AUTOSAR XML (schema 4-0-3)
package /AUTOSAR_Dcm/ImplementationDataTypes
  61 x impl type:
    DataArrayType_DcmDspData_PlatformSoftwareVersion: category=ARRAY
      element DataArrayType: array-size=14, array-size-semantics=FIXED-SIZE, implementation-data-type=uint8
    DataArrayType_DcmDspData_InputOutputControlbyIdentifier_Supportedcheck: category=ARRAY
      element DataArrayType: array-size=4, array-size-semantics=FIXED-SIZE, implementation-data-type=uint8
    DataArrayType_DcmDspData_InputOutputRecordLocalIdentifier1: category=ARRAY
      element DataArrayType: array-size=20, array-size-semantics=FIXED-SIZE, implementation-data-type=uint8
    Dcm_ProtocolType:
      category=VALUE
      base-type=uint8
      compu {0x00=DCM_OBD_ON_CAN, 0x01=DCM_OBD_ON_FLEXRAY, 0x02=DCM_OBD_ON_IP, 0x03=DCM_UDS_ON_CAN, 0x04=DCM_UDS_ON_FLEXRAY, 0x05=DCM_UDS_ON_IP, 0x06=DCM_ROE_ON_CAN, 0x07=DCM_ROE_ON_FLEXRAY, 0x08=DCM_ROE_ON_IP, 0x09=DCM_PERIODICTRANS_ON_CAN, 0x0A=DCM_PERIODICTRANS_ON_FLEXRAY, 0x0B=DCM_PERIODICTRANS_ON_IP, 0x0C=DCM_NO_ACTIVE_PROTOCOL, 0xF0=DCM_SUPPLIER_1, 0xF1=DCM_SUPPLIER_2, 0xF2=DCM_SUPPLIER_3, 0xF3=DCM_SUPPLIER_4, 0xF4=DCM_SUPPLIER_5, 0xF5=DCM_SUPPLIER_6, 0xF6=DCM_SUPPLIER_7, 0xF7=DCM_SUPPLIER_8, 0xF8=DCM_SUPPLIER_9, 0xF9=DCM_SUPPLIER_10, 0xFA=DCM_SUPPLIER_11, 0xFB=DCM_SUPPLIER_12, 0xFC=DCM_SUPPLIER_13, 0xFD=DCM_SUPPLIER_14, 0xFE=DCM_SUPPLIER_15, 0x0E=DCM_OBD_ON_UDS, 0x0F=DCM_ZEV_ON_UDS}
      range raw 0x00..0xFE
    Dcm_ResponseDataArrayType: category=ARRAY
      element RequestDataArray: array-size=512, array-size-semantics=FIXED-SIZE, implementation-data-type=uint8
    DataArrayType_DcmDspData_SecureBootEnable: category=ARRAY
      element DataArrayType: array-size=1, array-size-semantics=FIXED-SIZE, implementation-data-type=uint8
    KeyArrayType_L10: category=ARRAY
      element KeyArrayType: array-size=256, array-size-semantics=FIXED-SIZE, implementation-data-type=uint8
    DataArrayType_DcmDspData_InputOutputControlbyIdentifier_13: category=ARRAY
      element DataArrayType: array-size=1, array-size-semantics=FIXED-SIZE, implementation-data-type=uint8
    DataArrayType_DcmDspData_ECUSoftwareUNITnumberDataIdentifier: category=ARRAY
      element DataArrayType: array-size=1, array-size-semantics=FIXED-SIZE, implementation-data-type=uint8
    Dcm_MsgLenType: category=VALUE, base-type=uint32, range raw 0..4294967295
    Dcm_PresentDateType: category=VALUE, base-type=uint8, range raw 0..255
    DataArrayType_DcmDspData_InputOutputControlbyIdentifier_18: category=ARRAY
      element DataArrayType: array-size=10, array-size-semantics=FIXED-SIZE, implementation-data-type=uint8
    DataArrayType_DcmDspData_SystemSupplierECUHardwareVersionNumberDataIdentifier: category=ARRAY
      element DataArrayType: array-size=4, array-size-semantics=FIXED-SIZE, implementation-data-type=uint8
    DataArrayType_DcmDspData_ChallengeRequest: category=ARRAY
      element DataArrayType: array-size=16, array-size-semantics=FIXED-SIZE, implementation-data-type=uint8
    DataArrayType_DcmDspData_VehicleManufacturerECUHardwareNumberDataIdentifier: category=ARRAY
      element DataArrayType: array-size=4, array-size-semantics=FIXED-SIZE, implementation-data-type=uint8
    Dcm_CertExpirationDateInfoType: category=ARRAY
      element expirationDate: array-size=3, array-size-semantics=FIXED-SIZE, implementation-data-type=uint8
    DataArrayType_DcmDspData_QRCodeWrite: category=ARRAY
      element DataArrayType: array-size=21, array-size-semantics=FIXED-SIZE, implementation-data-type=uint8
    Dcm_StatusType: category=VALUE, base-type=uint8, compu {0x00=DCM_E_OK, 0x08=DCM_E_REQUEST_NOT_ACCEPTED, 0x05=DCM_E_PROTOCOL_NOT_ALLOWED, 0x06=DCM_E_ROE_NOT_ACCEPTED, 0x07=DCM_E_PERIODICID_NOT_ACCEPTED, 0x11=DCM_E_COMPARE_KEY_FAILED}, range raw 0x00..0x11
    Dcm_EcuStartModeType: category=VALUE, base-type=uint8, compu {0x00=DCM_COLD_START, 0x01=DCM_WARM_START}, range raw 0x00..0x01
    DataArrayType_DcmDspData_ECUSoftwareUNIT1VersionDataIdentifier: category=ARRAY
      element DataArrayType: array-size=5, array-size-semantics=FIXED-SIZE, implementation-data-type=uint8
    KeyArrayType_L9: category=ARRAY
      element KeyArrayType: array-size=8, array-size-semantics=FIXED-SIZE, implementation-data-type=uint8
    DataArrayType_DcmDspData_SoftwareVersionforHKMCVehiclemanufactureDataIdentifier: category=ARRAY
      element DataArrayType: array-size=5, array-size-semantics=FIXED-SIZE, implementation-data-type=uint8
    Dcm_ReturnReadMemoryType: category=VALUE, base-type=uint8, compu {0x02=DCM_READ_FAILED, 0x03=DCM_READ_FORCE_RCRRP, 0x00=DCM_READ_OK, 0x01=DCM_READ_PENDING}, range raw 0x00..0x03
    DataArrayType_DcmDspData_InputOutputControlbyIdentifier_17: category=ARRAY
      element DataArrayType: array-size=1, array-size-semantics=FIXED-SIZE, implementation-data-type=uint8
    DataArrayType_DcmDspData_PlatformHardwareVersion: category=ARRAY
      element DataArrayType: array-size=11, array-size-semantics=FIXED-SIZE, implementation-data-type=uint8
    DTRStatusType: category=VALUE, base-type=uint8, range raw 0..255
    Dcm_CertAuthorizationInfoType: category=ARRAY
      element authorization: array-size=4, array-size-semantics=FIXED-SIZE, implementation-data-type=uint8
    DataArrayType_DcmDspData_EcuInfoWrite: category=ARRAY
      element DataArrayType: array-size=18, array-size-semantics=FIXED-SIZE, implementation-data-type=uint8
    Dcm_ConfirmationStatusType: category=VALUE, base-type=uint8, compu {0x00=DCM_RES_POS_OK, 0x01=DCM_RES_POS_NOT_OK, 0x02=DCM_RES_NEG_OK, 0x03=DCM_RES_NEG_NOT_OK}, range raw 0x00..0x03
    DataArrayType_DcmDspData_VehicleManufacturerSparePartNumberDataIdentifier: category=ARRAY
      element DataArrayType: array-size=10, array-size-semantics=FIXED-SIZE, implementation-data-type=uint8
    DataArrayType_DcmDspData_InputOutputControlbyIdentifier_16: category=ARRAY
      element DataArrayType: array-size=1, array-size-semantics=FIXED-SIZE, implementation-data-type=uint8
    Dcm_CertInfoType: category=STRUCTURE
      element authorization: implementation-data-type=Dcm_CertAuthorizationInfoType
      element expirationDate: implementation-data-type=Dcm_CertExpirationDateInfoType
    Dcm_NegativeResponseCodeType:
      category=VALUE
      base-type=uint8
      compu {0x00=DCM_E_POSITIVERESPONSE, 0x10=DCM_E_GENERALREJECT, 0x11=DCM_E_SERVICENOTSUPPORTED, 0x12=DCM_E_SUBFUNCTIONNOTSUPPORTED, 0x13=DCM_E_INCORRECTMESSAGELENGTHORINVALIDFORMAT, 0x14=DCM_E_RESPONSETOOLONG, 0x21=DCM_E_BUSYREPEATREQUEST, 0x22=DCM_E_CONDITIONSNOTCORRECT, 0x24=DCM_E_REQUESTSEQUENCEERROR, 0x25=DCM_E_NORESPONSEFROMSUBNETCOMPONENT, 0x26=DCM_E_FAILUREPREVENTSEXECUTIONOFREQUESTEDACTION, 0x31=DCM_E_REQUESTOUTOFRANGE, 0x33=DCM_E_SECURITYACCESSDENIED, 0x35=DCM_E_INVALIDKEY, 0x36=DCM_E_EXCEEDNUMBEROFATTEMPTS, 0x37=DCM_E_REQUIREDTIMEDELAYNOTEXPIRED, 0x70=DCM_E_UPLOADDOWNLOADNOTACCEPTED, 0x71=DCM_E_TRANSFERDATASUSPENDED, 0x72=DCM_E_GENERALPROGRAMMINGFAILURE, 0x73=DCM_E_WRONGBLOCKSEQUENCECOUNTER, 0x7E=DCM_E_SUBFUNCTIONNOTSUPPORTEDINACTIVESESSION, 0x7F=DCM_E_SERVICENOTSUPPORTEDINACTIVESESSION, 0x81=DCM_E_RPMTOOHIGH, 0x82=DCM_E_RPMTOOLOW, 0x83=DCM_E_ENGINEISRUNNING, 0x84=DCM_E_ENGINEISNOTRUNNING, 0x85=DCM_E_ENGINERUNTIMETOOLOW, 0x86=DCM_E_TEMPERATURETOOHIGH, 0x87=DCM_E_TEMPERATURETOOLOW, 0x88=DCM_E_VEHICLESPEEDTOOHIGH, 0x89=DCM_E_VEHICLESPEEDTOOLOW, 0x8A=DCM_E_THROTTLE_PEDALTOOHIGH, 0x8B=DCM_E_THROTTLE_PEDALTOOLOW, 0x8C=DCM_E_TRANSMISSIONRANGENOTINNEUTRAL, 0x8D=DCM_E_TRANSMISSIONRANGENOTINGEAR, 0x8F=DCM_E_BRAKESWITCH_NOTCLOSED, 0x90=DCM_E_SHIFTERLEVERNOTINPARK, 0x91=DCM_E_TORQUECONVERTERCLUTCHLOCKED, 0x92=DCM_E_VOLTAGETOOHIGH, 0x93=DCM_E_VOLTAGETOOLOW, 0xF0=DCM_E_CRLINTEGRITYCHECKFAILED, 0xF1=DCM_E_CRLEXPIRED, 0xF2=DCM_E_ROLEANDRIGHTOFCERTIFICATEDENIED, 0xF3=DCM_E_SECURITYACCESSDENIEDFRONCGW, 0xF4=DCM_E_LOWERVERSIONDOWNLOADATTEMPT, 0xF5=DCM_E_SERVICENOTSUPPORTEDINACTIVECONNECTION, 0xF6=DCM_E_VMSCNC_6, 0xF7=DCM_E_VMSCNC_7, 0xF8=DCM_E_VMSCNC_8, 0xF9=DCM_E_VMSCNC_9, 0xFA=DCM_E_VMSCNC_A, 0xFB=DCM_E_VMSCNC_B, 0xFC=DCM_E_VMSCNC_C, 0xFD=DCM_E_VMSCNC_D, 0xFE=DCM_E_VMSCNC_E, 0x50=DCM_E_CERTIFICATEVERIFICATIONFAILEDINVALIDTIMEPERIOD, 0x51=DCM_E_CERTIFICATEVERIFICATIONFAILEDINVALIDSIGNATURE, 0x52=DCM_E_CERTIFICATEVERIFICATIONFAILEDINVALIDCHAINOFTRUST, 0x53=DCM_E_CERTIFICATEVERIFICATIONFAILEDINVALIDTYPE, 0x54=DCM_E_CERTIFICATEVERIFICATIONFAILEDINVALIDFORMAT, 0x55=DCM_E_CERTIFICATEVERIFICATIONFAILEDINVALIDCONTENT, 0x56=DCM_E_CERTIFICATEVERIFICATIONFAILEDINVALIDSCOPE, 0x57=DCM_E_CERTIFICATEVERIFICATIONFAILEDINVALIDCERTIFICATE, 0x58=DCM_E_OWNERSHIPVERIFICATIONFAILED, 0x59=DCM_E_CHALLENGECALCULATIONFAILED, 0x5A=DCM_E_SETTINGACCESSRIGHTSFAILED, 0x5B=DCM_E_SESSIONKEYCREATIONDERIVATIONFAILED, 0x5C=DCM_E_CONFIGURATIONDATAUSAGEFAILED, 0x5D=DCM_E_DEAUTHENTICATIONFAILED, 0x34=DCM_E_AUTHENTICATIONREQUIRED}
      range raw 0x00..0xFF
    SeedArrayType_L10: category=ARRAY
      element SeedArrayType: array-size=8, array-size-semantics=FIXED-SIZE, implementation-data-type=uint8
    Dcm_SesCtrlType: category=VALUE, base-type=uint8, compu {0x01=DCM_DEFAULT_SESSION, 0x02=DCM_PROGRAMMING_SESSION, 0x03=DCM_EXTENDED_DIAGNOSTIC_SESSION, 0x04=DCM_SAFETY_SYSTEM_DIAGNOSTIC_SESSION, 0x10=DCM_EXTENDED_DIAGNOSTIC_MODE_10H, 0x05=DCM_ECU_PROGRAMMING_MODE_05H, 0x50=DCM_QUIESCENT_CURRENT_DIAGNOSTIC_MODE_START, 0x51=DCM_SLEEP_MODE_START_REQUEST, 0xFF=DCM_ALL_SESSION_LEVEL}, range raw 0x01..0xFF
    Dcm_IdContextType: category=VALUE, base-type=uint8, range raw 0..255
    DataArrayType_DcmDspData_NML_LogData: category=ARRAY
      element DataArrayType: array-size=200, array-size-semantics=FIXED-SIZE, implementation-data-type=uint8
    Dcm_CommunicationModeType:
      category=VALUE
      base-type=uint8
      compu {0x00=DCM_ENABLE_RX_TX_NORM, 0x01=DCM_ENABLE_RX_DISABLE_TX_NORM, 0x02=DCM_DISABLE_RX_ENABLE_TX_NORM, 0x03=DCM_DISABLE_RX_TX_NORMAL, 0x04=DCM_ENABLE_RX_TX_NM, 0x05=DCM_ENABLE_RX_DISABLE_TX_NM, 0x06=DCM_DISABLE_RX_ENABLE_TX_NM, 0x07=DCM_DISABLE_RX_TX_NM, 0x08=DCM_ENABLE_RX_TX_NORM_NM, 0x09=DCM_ENABLE_RX_DISABLE_TX_NORM_NM, 0x0A=DCM_DISABLE_RX_ENABLE_TX_NORM_NM, 0x0B=DCM_DISABLE_RX_TX_NORM_NM, 0x03=DCM_DISABLE_RX_TX_NORM}
      range raw 0x00..0x0B
    DataArrayType_DcmDspData_ECUSecurityInformationDataIdentifier: category=ARRAY
      element DataArrayType: array-size=3, array-size-semantics=FIXED-SIZE, implementation-data-type=uint8
    RequestDataArray: category=ARRAY
      element RequestDataArray: array-size=2050, array-size-semantics=FIXED-SIZE, implementation-data-type=uint8
    DataArrayType_DcmDspData_InputOutputControlbyIdentifier_12: category=ARRAY
      element DataArrayType: array-size=1, array-size-semantics=FIXED-SIZE, implementation-data-type=uint8
    StartDataOutType_RID_0300h_OTAReady_Out_RoutineStatus: category=VALUE, base-type=uint8, range raw 0..255
    DataArrayType_DcmDspData_ECUSerialNumberDataIdentifier: category=ARRAY
      element DataArrayType: array-size=15, array-size-semantics=FIXED-SIZE, implementation-data-type=uint8
    Dcm_ProgConditionsType: category=STRUCTURE
      9 x element, all with category=TYPE_REFERENCE:
        ConnectionId: implementation-data-type=uint16
        TesterSourceAddr: implementation-data-type=uint16
        ProtocolId: implementation-data-type=uint8
        Sid: implementation-data-type=uint8
        SubFncId: implementation-data-type=uint8
        ReprogramingRequest: implementation-data-type=boolean
        ApplUpdated: implementation-data-type=boolean
        ResponseRequired: implementation-data-type=boolean
        SecLvInfo: implementation-data-type=uint8
    Dcm_RoeStateType: category=VALUE, base-type=uint8, compu {0x00=DCM_ROE_ACTIVE, 0x01=DCM_ROE_UNACTIVE}, range raw 0x00..0x01
    DataArrayType_DcmDspData_ECUSupplierCodeDataIdentifier: category=ARRAY
      element DataArrayType: array-size=4, array-size-semantics=FIXED-SIZE, implementation-data-type=uint8
    DataArrayType_DcmDspData_NonSleepCollectedEachEcuDataDataIdentifier: category=ARRAY
      element DataArrayType: array-size=15, array-size-semantics=FIXED-SIZE, implementation-data-type=uint8
    DataArrayType_DcmDspData_SystemName: category=ARRAY
      element DataArrayType: array-size=3, array-size-semantics=FIXED-SIZE, implementation-data-type=uint8
    Dcm_ReturnWriteMemoryType: category=VALUE, base-type=uint8, compu {0x02=DCM_WRITE_FAILED, 0x03=DCM_WRITE_FORCE_RCRRP, 0x00=DCM_WRITE_OK, 0x01=DCM_WRITE_PENDING}, range raw 0x00..0x03
    DataArrayType_DcmDspData_ECUSoftwareUnit1IVDDataIdentifier: category=ARRAY
      element DataArrayType: array-size=32, array-size-semantics=FIXED-SIZE, implementation-data-type=uint8
    SeedArrayType_L9: category=ARRAY
      element SeedArrayType: array-size=8, array-size-semantics=FIXED-SIZE, implementation-data-type=uint8
    DataArrayType_DcmDspData_EcuInfoRead: category=ARRAY
      element DataArrayType: array-size=72, array-size-semantics=FIXED-SIZE, implementation-data-type=uint8
    DataArrayType_DcmDspData_InputOutputRecordLocalIdentifier2: category=ARRAY
      element DataArrayType: array-size=10, array-size-semantics=FIXED-SIZE, implementation-data-type=uint8
    Dcm_SecLevelType: category=VALUE, base-type=uint8, compu {0x00=DCM_SEC_LEV_LOCKED, 0x01=DCM_SEC_LEV_L1, 0x09=DCM_SEC_LEV_L9, 0x21=DCM_SEC_LEV_L21, 0xFF=DCM_SEC_LEV_ALL}, range raw 0x00..0xFF
    DataArrayType_DcmDspData_CANDataBaseVersionNumberDataIdentifier: category=ARRAY
      element DataArrayType: array-size=4, array-size-semantics=FIXED-SIZE, implementation-data-type=uint8
    DataArrayType_DcmDspData_ECUManufacturingDateDataIdentifier: category=ARRAY
      element DataArrayType: array-size=4, array-size-semantics=FIXED-SIZE, implementation-data-type=uint8
    DataArrayType_DcmDspData_InputOutputControlbyIdentifier_11: category=ARRAY
      element DataArrayType: array-size=1, array-size-semantics=FIXED-SIZE, implementation-data-type=uint8
    Dcm_OpStatusType: category=VALUE, base-type=uint8, compu {0x00=DCM_INITIAL, 0x01=DCM_PENDING, 0x02=DCM_CANCEL, 0x03=DCM_FORCE_RCRRP_OK}, range raw 0x00..0x03
    Dcm_MsgItemType: category=VALUE, base-type=uint8, range raw 0..255
    Dcm_CerHolderReferenceInfoType: category=ARRAY
      element Dcm_CerHolderReferenceInfoType: array-size=16, array-size-semantics=FIXED-SIZE, implementation-data-type=uint8
    DataArrayType_DcmDspData_LocalRXSWINDataIdentifier: category=ARRAY
      element DataArrayType: array-size=128, array-size-semantics=FIXED-SIZE, implementation-data-type=uint8
package /AUTOSAR_Dcm/ClientServerInterfaces
  8 x client server interface, all with is-service=true:
    DCMServices
      6 x operation, all with possible-error=DCMServices/E_NOT_OK:
        ResetToDefaultSession
        GetCertificationInfo
          arg CertInfo: type=Dcm_CertInfoType, direction=OUT
        GetSecurityLevel
          arg SecLevel: type=Dcm_SecLevelType, direction=OUT
        GetActiveProtocol
          arg ActiveProtocol: type=Dcm_ProtocolType, direction=OUT
        GetCertHolderReference
          arg CertHolderReferenceInfo: type=Dcm_CerHolderReferenceInfoType, direction=OUT
        GetSesCtrlType
          arg SesCtrlType: type=Dcm_SesCtrlType, direction=OUT
      error E_NOT_OK: error-code=1
    SecurityAccess_L9
      4 x operation:
        GetSecurityAttemptCounter: possible-error=[SecurityAccess_L9/E_NOT_OK, SecurityAccess_L9/DCM_E_PENDING]
          arg OpStatus: type=Dcm_OpStatusType, direction=IN
          arg AttemptCounter: type=uint8, direction=OUT
        GetSeed: possible-error=[SecurityAccess_L9/E_NOT_OK, SecurityAccess_L9/DCM_E_PENDING]
          arg OpStatus: type=Dcm_OpStatusType, direction=IN
          arg Seed: type=SeedArrayType_L9, direction=OUT
          arg ErrorCode: type=Dcm_NegativeResponseCodeType, direction=OUT
        CompareKey: possible-error=[SecurityAccess_L9/E_NOT_OK, SecurityAccess_L9/DCM_E_PENDING, SecurityAccess_L9/DCM_E_COMPARE_KEY_FAILED]
          arg Key: type=KeyArrayType_L9, direction=IN
          arg OpStatus: type=Dcm_OpStatusType, direction=IN
        SetSecurityAttemptCounter: possible-error=[SecurityAccess_L9/E_NOT_OK, SecurityAccess_L9/DCM_E_PENDING]
          arg OpStatus: type=Dcm_OpStatusType, direction=IN
          arg AttemptCounter: type=uint8, direction=IN
      error E_NOT_OK: error-code=1
      error DCM_E_PENDING: error-code=10
      error DCM_E_COMPARE_KEY_FAILED: error-code=11
    DTRServices
      operation GetDTRValue: possible-error=DTRServices/E_NOT_OK
        5 x arg:
          Opstatus: type=Dcm_OpStatusType, direction=IN
          Testval: type=uint16, direction=OUT
          Minlimit: type=uint16, direction=OUT
          Maxlimit: type=uint16, direction=OUT
          Status: type=DTRStatusType, direction=OUT
      error E_NOT_OK: error-code=1
    CallbackDCMPresentDate
      operation GetPresentDate: possible-error=CallbackDCMPresentDate/E_NOT_OK
        arg Date: type=Dcm_PresentDateType, direction=OUT
      error E_NOT_OK: error-code=1
    SecurityAccess_L10
      4 x operation:
        GetSecurityAttemptCounter: possible-error=[SecurityAccess_L10/E_NOT_OK, SecurityAccess_L10/DCM_E_PENDING]
          arg OpStatus: type=Dcm_OpStatusType, direction=IN
          arg AttemptCounter: type=uint8, direction=OUT
        GetSeed: possible-error=[SecurityAccess_L10/E_NOT_OK, SecurityAccess_L10/DCM_E_PENDING]
          arg OpStatus: type=Dcm_OpStatusType, direction=IN
          arg Seed: type=SeedArrayType_L10, direction=OUT
          arg ErrorCode: type=Dcm_NegativeResponseCodeType, direction=OUT
        CompareKey: possible-error=[SecurityAccess_L10/E_NOT_OK, SecurityAccess_L10/DCM_E_PENDING, SecurityAccess_L10/DCM_E_COMPARE_KEY_FAILED]
          arg Key: type=KeyArrayType_L10, direction=IN
          arg OpStatus: type=Dcm_OpStatusType, direction=IN
        SetSecurityAttemptCounter: possible-error=[SecurityAccess_L10/E_NOT_OK, SecurityAccess_L10/DCM_E_PENDING]
          arg OpStatus: type=Dcm_OpStatusType, direction=IN
          arg AttemptCounter: type=uint8, direction=IN
      error E_NOT_OK: error-code=1
      error DCM_E_PENDING: error-code=10
      error DCM_E_COMPARE_KEY_FAILED: error-code=11
    ServiceRequestNotification
      operation Confirmation: possible-error=ServiceRequestNotification/E_NOT_OK
        4 x arg, all with direction=IN:
          SID: type=uint8
          ReqType: type=uint8
          SourceAddress: type=uint16
          ConfirmationStatus: type=Dcm_ConfirmationStatusType
      operation Indication: possible-error=[ServiceRequestNotification/E_NOT_OK, E_REQUEST_NOT_ACCEPTED]
        6 x arg:
          SID: type=uint8, direction=IN
          RequestData: type=RequestDataArray, direction=IN
          DataSize: type=uint16, direction=IN
          ReqType: type=uint8, direction=IN
          SourceAddress: type=uint16, direction=IN
          ErrorCode: type=Dcm_NegativeResponseCodeType, direction=OUT
      error E_NOT_OK: error-code=1
      error E_REQUEST_NOT_ACCEPTED: error-code=8
    RoutineServices_RID_0300h_OTAReady
      operation Start: possible-error=[RoutineServices_RID_0300h_OTAReady/E_NOT_OK, DCM_E_FORCE_RCRRP, RoutineServices_RID_0300h_OTAReady/DCM_E_PENDING]
        arg OpStatus: type=Dcm_OpStatusType, direction=IN
        arg DataOut_Out_RoutineStatus: type=StartDataOutType_RID_0300h_OTAReady_Out_RoutineStatus, direction=OUT
        arg ErrorCode: type=Dcm_NegativeResponseCodeType, direction=OUT
      error E_NOT_OK: error-code=1
      error DCM_E_FORCE_RCRRP: error-code=12
      error DCM_E_PENDING: error-code=10
    CallbackDCMRequestServices
      operation StopProtocol: possible-error=CallbackDCMRequestServices/E_NOT_OK
        arg ProtocolID: type=Dcm_ProtocolType, direction=IN
      operation StartProtocol: possible-error=[CallbackDCMRequestServices/E_NOT_OK, E_PROTOCOL_NOT_ALLOWED]
        arg ProtocolID: type=Dcm_ProtocolType, direction=IN
      error E_NOT_OK: error-code=1
      error E_PROTOCOL_NOT_ALLOWED: error-code=5
package /AUTOSAR_Dcm/ServiceSwComponentTypes
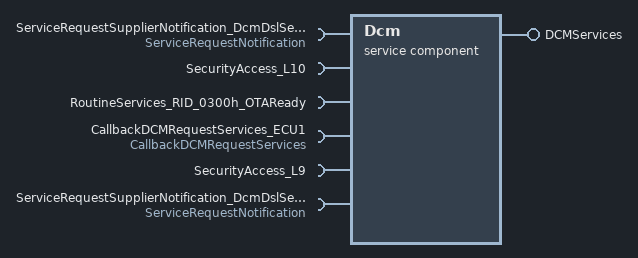
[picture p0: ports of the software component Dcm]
  service sw component type Dcm
    provide port DCMServices: provided-interface=DCMServices
      provided-com-specs:
        operation=ResetToDefaultSession, queue-length=1
        operation=GetCertificationInfo, queue-length=1
        operation=GetSecurityLevel, queue-length=1
        operation=GetActiveProtocol, queue-length=1
        operation=GetCertHolderReference, queue-length=1
        operation=GetSesCtrlType, queue-length=1
    6 x require port:
      ServiceRequestSupplierNotification_DcmDslServiceRequestSupplierNotification0: required-com-specs=[Confirmation, Indication], required-interface=ServiceRequestNotification
      SecurityAccess_L10: required-interface=SecurityAccess_L10
        required-com-specs:
          SecurityAccess_L10/GetSecurityAttemptCounter
          SecurityAccess_L10/GetSeed
          SecurityAccess_L10/CompareKey
          SecurityAccess_L10/SetSecurityAttemptCounter
      RoutineServices_RID_0300h_OTAReady: client-com-spec=Start, required-interface=RoutineServices_RID_0300h_OTAReady
      CallbackDCMRequestServices_ECU1: required-com-specs=[StopProtocol, StartProtocol], required-interface=CallbackDCMRequestServices
      SecurityAccess_L9: required-interface=SecurityAccess_L9
        required-com-specs:
          SecurityAccess_L9/GetSecurityAttemptCounter
          SecurityAccess_L9/GetSeed
          SecurityAccess_L9/CompareKey
          SecurityAccess_L9/SetSecurityAttemptCounter
      ServiceRequestSupplierNotification_DcmDslServiceRequestSupplierNotification1: required-com-specs=[Confirmation, Indication], required-interface=ServiceRequestNotification
    behavior DcmInternalBehavior: handle-termination-and-restart=NO-SUPPORT, included-data-type-set=data-type=[DataArrayType_DcmDspData_PlatformSoftwareVersion, DataArrayType_DcmDspData_InputOutputControlbyIdentifier_Supportedcheck, DataArrayType_DcmDspData_InputOutputRecordLocalIdentifier1, Dcm_ProtocolType, Dcm_ResponseDataArrayType, DataArrayType_DcmDspData_SecureBootEnable, KeyArrayType_L10, DataArrayType_DcmDspData_InputOutputControlbyIdentifier_13, DataArrayType_DcmDspData_ECUSoftwareUNITnumberDataIdentifier, Dcm_MsgLenType, Dcm_PresentDateType, DataArrayType_DcmDspData_InputOutputControlbyIdentifier_18, DataArrayType_DcmDspData_SystemSupplierECUHardwareVersionNumberDataIdentifier, DataArrayType_DcmDspData_ChallengeRequest, DataArrayType_DcmDspData_VehicleManufacturerECUHardwareNumberDataIdentifier, Dcm_CertExpirationDateInfoType, DataArrayType_DcmDspData_QRCodeWrite, Dcm_StatusType, Dcm_EcuStartModeType, DataArrayType_DcmDspData_ECUSoftwareUNIT1VersionDataIdentifier, KeyArrayType_L9, DataArrayType_DcmDspData_SoftwareVersionforHKMCVehiclemanufactureDataIdentifier, Dcm_ReturnReadMemoryType, DataArrayType_DcmDspData_InputOutputControlbyIdentifier_17, DataArrayType_DcmDspData_PlatformHardwareVersion, DTRStatusType, Dcm_CertAuthorizationInfoType, DataArrayType_DcmDspData_EcuInfoWrite, Dcm_ConfirmationStatusType, DataArrayType_DcmDspData_VehicleManufacturerSparePartNumberDataIdentifier, DataArrayType_DcmDspData_InputOutputControlbyIdentifier_16, Dcm_CertInfoType, Dcm_NegativeResponseCodeType, SeedArrayType_L10, Dcm_SesCtrlType, Dcm_IdContextType, DataArrayType_DcmDspData_NML_LogData, Dcm_CommunicationModeType, DataArrayType_DcmDspData_ECUSecurityInformationDataIdentifier, RequestDataArray, DataArrayType_DcmDspData_InputOutputControlbyIdentifier_12, StartDataOutType_RID_0300h_OTAReady_Out_RoutineStatus, DataArrayType_DcmDspData_ECUSerialNumberDataIdentifier, Dcm_ProgConditionsType, Dcm_RoeStateType, DataArrayType_DcmDspData_ECUSupplierCodeDataIdentifier, DataArrayType_DcmDspData_NonSleepCollectedEachEcuDataDataIdentifier, DataArrayType_DcmDspData_SystemName, Dcm_ReturnWriteMemoryType, DataArrayType_DcmDspData_ECUSoftwareUnit1IVDDataIdentifier, SeedArrayType_L9, DataArrayType_DcmDspData_EcuInfoRead, DataArrayType_DcmDspData_InputOutputRecordLocalIdentifier2, Dcm_SecLevelType, DataArrayType_DcmDspData_CANDataBaseVersionNumberDataIdentifier, DataArrayType_DcmDspData_ECUManufacturingDateDataIdentifier, DataArrayType_DcmDspData_InputOutputControlbyIdentifier_11, Dcm_OpStatusType, Dcm_MsgItemType, Dcm_CerHolderReferenceInfoType, DataArrayType_DcmDspData_LocalRXSWINDataIdentifier]
      6 x operation invoked event:
        OIE_DCMServices_ResetToDefaultSession: start-on-event=ResetToDefaultSession, operation=DCMServices.ResetToDefaultSession
        OIE_DCMServices_GetCertificationInfo: start-on-event=GetCertificationInfo, operation=DCMServices.GetCertificationInfo
        OIE_DCMServices_GetSecurityLevel: start-on-event=GetSecurityLevel, operation=DCMServices.GetSecurityLevel
        OIE_DCMServices_GetActiveProtocol: start-on-event=GetActiveProtocol, operation=DCMServices.GetActiveProtocol
        OIE_DCMServices_GetCertHolderReference: start-on-event=GetCertHolderReference, operation=DCMServices.GetCertHolderReference
        OIE_DCMServices_GetSesCtrlType: start-on-event=GetSesCtrlType, operation=DCMServices.GetSesCtrlType
      7 x runnable:
        ResetToDefaultSession: can-be-invoked-concurrently=true, symbol=Dcm_ResetToDefaultSession
        GetCertificationInfo: can-be-invoked-concurrently=true, symbol=Dcm_GetCertificationInfo
        GetSecurityLevel: can-be-invoked-concurrently=true, symbol=Dcm_GetSecurityLevel
        GetActiveProtocol: can-be-invoked-concurrently=true, symbol=Dcm_GetActiveProtocol
        GetCertHolderReference: can-be-invoked-concurrently=true, symbol=Dcm_GetCertHolderReference
        GetSesCtrlType: can-be-invoked-concurrently=true, symbol=Dcm_GetSesCtrlType
        MainFunction: symbol=Dcm_MainFunction
          15 x sync call, all with timeout=0:
            SSCP_ServiceRequestSupplierNotification_DcmDslServiceRequestSupplierNotification0_Confirmation: operation=ServiceRequestSupplierNotification_DcmDslServiceRequestSupplierNotification0.Confirmation
            SSCP_ServiceRequestSupplierNotification_DcmDslServiceRequestSupplierNotification0_Indication: operation=ServiceRequestSupplierNotification_DcmDslServiceRequestSupplierNotification0.Indication
            SSCP_SecurityAccess_L10_GetSecurityAttemptCounter: operation=SecurityAccess_L10.GetSecurityAttemptCounter
            SSCP_SecurityAccess_L10_GetSeed: operation=SecurityAccess_L10.GetSeed
            SSCP_SecurityAccess_L10_CompareKey: operation=SecurityAccess_L10.CompareKey
            SSCP_SecurityAccess_L10_SetSecurityAttemptCounter: operation=SecurityAccess_L10.SetSecurityAttemptCounter
            SSCP_RoutineServices_RID_0300h_OTAReady_Start: operation=RoutineServices_RID_0300h_OTAReady.Start
            SSCP_CallbackDCMRequestServices_ECU1_StopProtocol: operation=CallbackDCMRequestServices_ECU1.StopProtocol
            SSCP_CallbackDCMRequestServices_ECU1_StartProtocol: operation=CallbackDCMRequestServices_ECU1.StartProtocol
            SSCP_SecurityAccess_L9_GetSecurityAttemptCounter: operation=SecurityAccess_L9.GetSecurityAttemptCounter
            SSCP_SecurityAccess_L9_GetSeed: operation=SecurityAccess_L9.GetSeed
            SSCP_SecurityAccess_L9_CompareKey: operation=SecurityAccess_L9.CompareKey
            SSCP_SecurityAccess_L9_SetSecurityAttemptCounter: operation=SecurityAccess_L9.SetSecurityAttemptCounter
            SSCP_ServiceRequestSupplierNotification_DcmDslServiceRequestSupplierNotification1_Confirmation: operation=ServiceRequestSupplierNotification_DcmDslServiceRequestSupplierNotification1.Confirmation
            SSCP_ServiceRequestSupplierNotification_DcmDslServiceRequestSupplierNotification1_Indication: operation=ServiceRequestSupplierNotification_DcmDslServiceRequestSupplierNotification1.Indication
  swc implementation Dcm_SwcImplementation: programming-language=C, sw-version=1.0.0.0, swc-bsw-mapping=SwcBswMapping_Dcm, vendor-id=0, behavior=DcmInternalBehavior
    code-descriptors:
      code CodeDescriptor: artifact-descriptors=autosar-engineering-object={short-label=Dcm_LibObjects, category=SWLIB, domain=AUTOSAR_DCM}
    resource consumption ResourceConsumption
  swc bsw mapping SwcBswMapping_Dcm: bsw-behavior=InternalBehavior_Dcm, swc-bsw-runnable-mapping{bsw-entity=BswSE_Dcm_MainFunction, swc-runnable=MainFunction}, swc-behavior=DcmInternalBehavior
